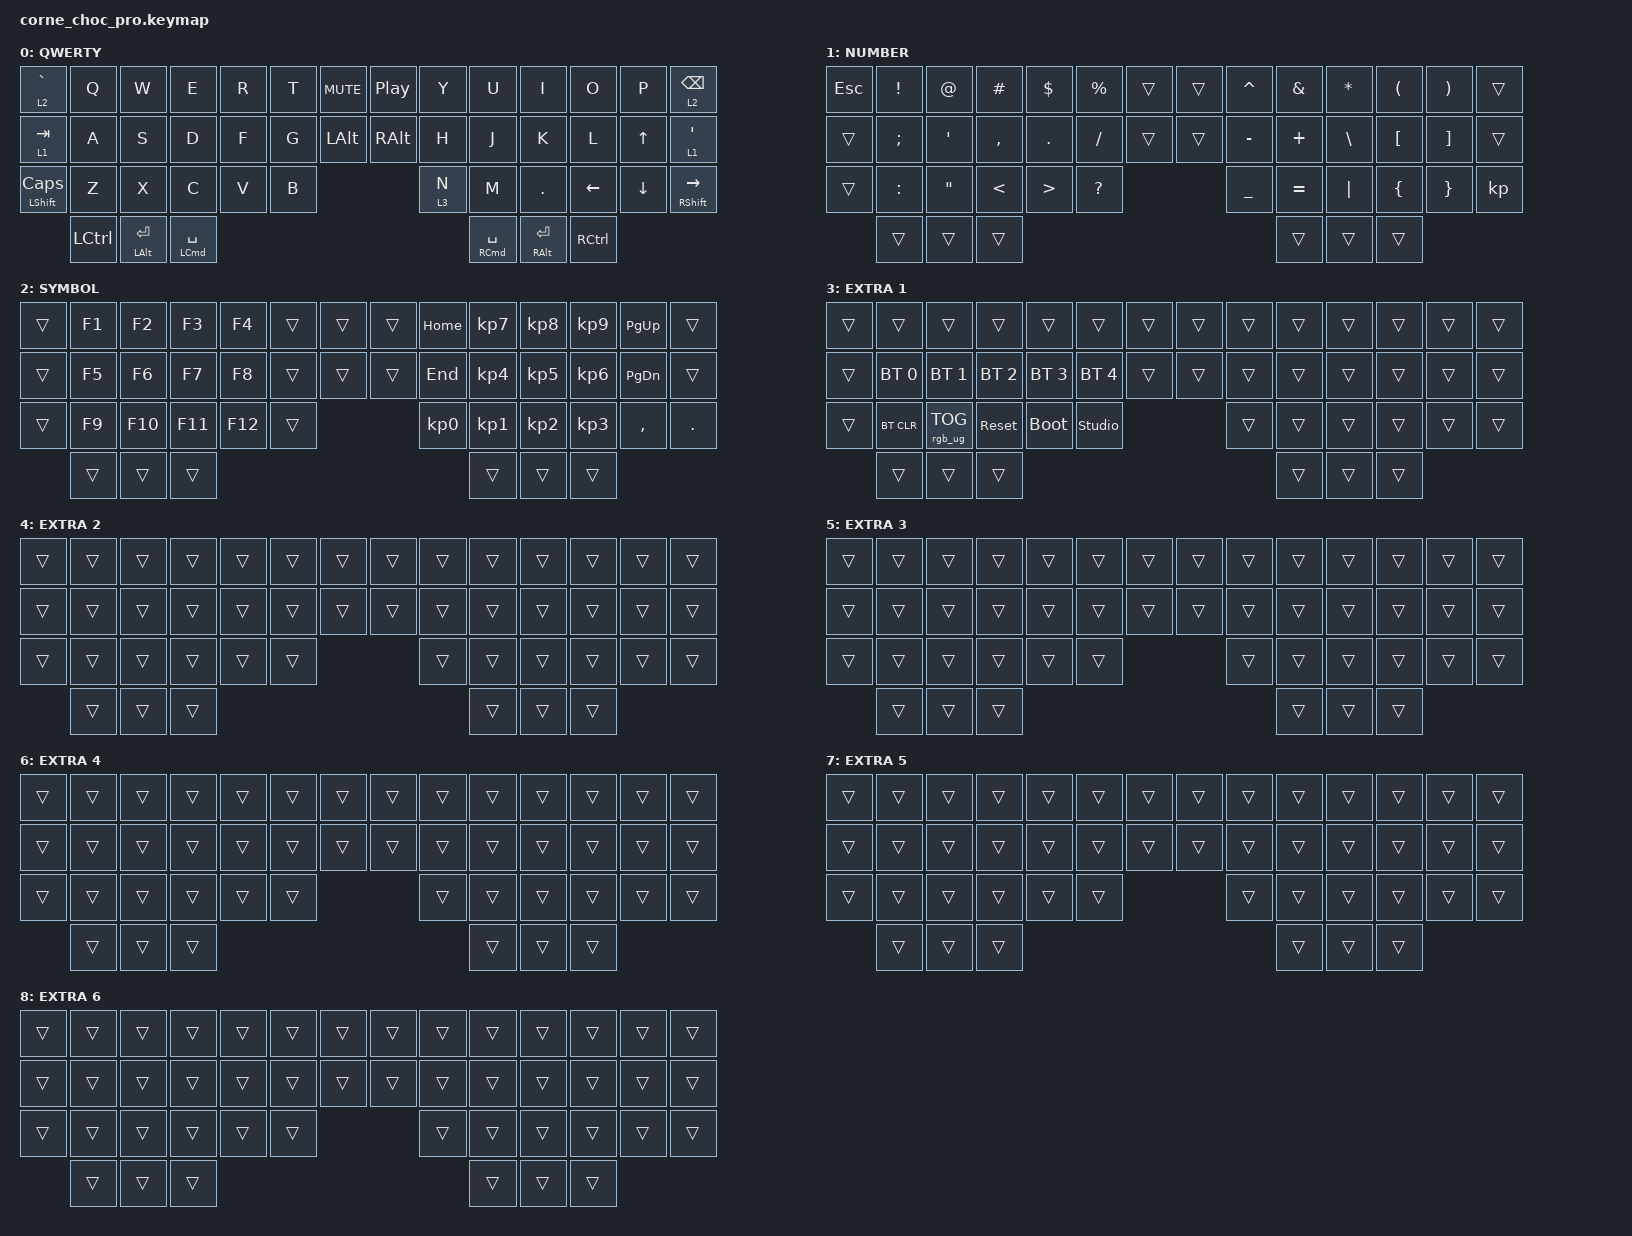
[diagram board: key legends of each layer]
/*
 * Copyright (c) 2020 The ZMK Contributors
 *
 * SPDX-License-Identifier: MIT
 */

#include <behaviors.dtsi>
#include <dt-bindings/zmk/keys.h>
#include <dt-bindings/zmk/bt.h>
#include <dt-bindings/zmk/rgb.h>

/ {
    chosen {
        zmk,physical-layout = &default_layout;
    };
};

/ {
    keymap {
        compatible = "zmk,keymap";

        default_layer {
            display-name = "QWERTY";
            // --------------------------------------------------------------------------------
            // |  `   |  Q  |  W  |  E  |  R  |  T  |  MUTE |  PP   |  Y  |  U  |  I  |  O  |  P  | BSPC |
            // | TAB  |  A  |  S  |  D  |  F  |  G  |  LALT |  RALT |  H  |  J  |  K  |  L  |  ;  |  '   |
            // | SHFT |  Z  |  X  |  C  |  V  |  B  |               |  N  |  M  |  ,  |  .  |  /  | SHFT |
            //                    | CTL | ENT | SPC |               | SPC | RET | CTL |
            bindings = <
                &lt 2 GRAVE     &kp Q &kp W &kp E &kp R &kp T &kp C_MUTE &kp C_PP &kp Y &kp U  &kp I   &kp O    &kp P     &lt 2 BSPC
                &lt 1 TAB       &kp A &kp S &kp D &kp F &kp G &kp LALT   &kp RALT &kp H &kp J  &kp K   &kp L    &kp UP    &lt 1 SQT
                &mt LSHFT CAPS  &kp Z &kp X &kp C &kp V &kp B                   &lt 3 N &kp M  &kp DOT &kp LEFT &kp DOWN  &mt RSHIFT RIGHT
                                &kp LCTRL &mt LALT RET &mt LCMD SPACE      &mt RCMD SPACE &mt RALT RET &kp RCTRL
            >;
            sensor-bindings = <&inc_dec_kp C_VOL_DN C_VOL_UP &inc_dec_kp PG_UP PG_DN &inc_dec_kp C_PREV C_NEXT &inc_dec_kp C_BRI_DN C_BRI_UP>;
        };

        lower_layer {
            display-name = "NUMBER";
            // -----------------------------------------------------------------------------------------
            // |     |  !  |  @  |  #  |  $  |  %  |     |     |  ^  |  &  |  *  |  (  |  )  |     |
            // |     |  ;  |  '  |  ,  |  .  |  /  |     |     |  -  |  +  |  \  |  [  |  ]  |     |
            // |     |  :  |  "  |  <  |  >  |  ?  |           |  _  |  =  | "|" |  {  |  }  |     |
            //                   |     |     |     |           |     |     |     |
            bindings = <
                &kp ESC &kp EXCL   &kp AT   &kp HASH   &kp DLLR   &kp PRCNT &trans &trans &kp CARET &kp AMPS  &kp ASTRK &kp LPAR &kp RPAR &trans
                &trans  &kp SEMI   &kp SQT  &kp COMMA  &kp PERIOD &kp FSLH  &trans &trans &kp MINUS &kp PLUS  &kp BSLH  &kp LBKT &kp RBKT &trans
                &trans  &kp COLON  &kp DQT  &kp LT     &kp GT     &kp QMARK               &kp UNDER &kp EQUAL &kp PIPE  &kp LBRC &kp RBRC &kp
                                            &trans     &trans     &trans                  &trans    &trans    &trans
            >;
        };

        raise_layer {
            display-name = "SYMBOL";
            // -----------------------------------------------------------------------------------------
            // |  TAB |  !  |  @  |  #  |  $  |  %  | LCTRL | RCTRL |  ^  |  &  |  *  |  (  |  )  | BSPC |
            // | CTRL |     |     |     |     |     |  LALT | RALT  |  -  |  =  |  [  |  ]  |  \  |  `   |
            // | SHFT |     |     |     |     |     |               |  _  |  +  |  {  |  }  | "|" |  ~   |
            //                    | GUI |     | SPC |               | ENT |     | ALT |
            // Suggestions
            // &bt BT_SEL 1, 2 and 3: left half, col 6, top, middle, bottom
            // function keys to layer 4, activate with BS hold,
            // key mappings left half only f1 f2 f3 f4 f5 f6
            //                             f7 f8 f9 f10 f12
            //                             &trns &trns &rgb_ug RGB_TOG &sys_reset &bootloader &studio_unlock

            bindings = <
                &trans  &kp F1  &kp F2  &kp F3  &kp F4  &trans  &trans  &trans  &kp HOME  &kp KP_N7 &kp KP_N8 &kp KP_N9 &kp PG_UP &trans
                &trans  &kp F5  &kp F6  &kp F7  &kp F8  &trans  &trans  &trans  &kp END   &kp KP_N4 &kp KP_N5 &kp KP_N6 &kp PG_DN &trans
                &trans  &kp F9  &kp F10 &kp F11 &kp F12 &trans                  &kp KP_N0 &kp KP_N1 &kp KP_N2 &kp KP_N3 &kp COMMA &kp PERIOD
                                        &trans  &trans  &trans                  &trans  &trans  &trans
            >;
        };

        extra_layer_1 {
            display-name = "EXTRA 1";
            // -----------------------------------------------------------------------------------------
            // |  TAB |  1  |  2  |  3  |  4  |  5    |  LCTRL | RCTRL |  6  |  7  |  8  |  9  |  0  | BSPC |
            // | CTRL | BT1 | BT2 | BT3 | BT4 | BT5   |  LALT  | RALT  | LFT | DWN |  UP | RGT |     |      |
            // | SHFT | BTCR| RGB | RST | BOOT| Unlock|        |       |     |     |     |     |     |      |
            //                    | GUI |     | SPC   |        | ENT   |     | ALT |
            bindings = <
                &trans  &trans  &trans  &trans  &trans  &trans  &trans    &trans &trans  &trans  &trans  &trans  &trans  &trans
                &trans &bt BT_SEL 0  &bt BT_SEL 1  &bt BT_SEL 2  &bt BT_SEL 3  &bt BT_SEL 4  &trans    &trans  &trans  &trans  &trans  &trans  &trans  &trans
                &trans &bt BT_CLR  &rgb_ug RGB_TOG &sys_reset   &bootloader  &studio_unlock                    &trans  &trans  &trans  &trans  &trans  &trans
                                                       &trans     &trans       &trans                          &trans  &trans  &trans
            >;
        };

        extra_layer_2 {
            display-name = "EXTRA 2";
            bindings = <
                &trans &trans &trans &trans &trans &trans &trans &trans &trans &trans &trans &trans &trans &trans
                &trans &trans &trans &trans &trans &trans &trans &trans &trans &trans &trans &trans &trans &trans
                &trans &trans &trans &trans &trans &trans               &trans &trans &trans &trans &trans &trans
                                     &trans &trans &trans               &trans &trans &trans
            >;
        };

        extra_layer_3 {
            display-name = "EXTRA 3";
            bindings = <
                &trans &trans &trans &trans &trans &trans &trans &trans &trans &trans &trans &trans &trans &trans
                &trans &trans &trans &trans &trans &trans &trans &trans &trans &trans &trans &trans &trans &trans
                &trans &trans &trans &trans &trans &trans               &trans &trans &trans &trans &trans &trans
                                     &trans &trans &trans               &trans &trans &trans
            >;
        };

        extra_layer_4 {
            display-name = "EXTRA 4";
            bindings = <
                &trans &trans &trans &trans &trans &trans &trans &trans &trans &trans &trans &trans &trans &trans
                &trans &trans &trans &trans &trans &trans &trans &trans &trans &trans &trans &trans &trans &trans
                &trans &trans &trans &trans &trans &trans               &trans &trans &trans &trans &trans &trans
                                     &trans &trans &trans               &trans &trans &trans
            >;
        };

        extra_layer_5 {
            display-name = "EXTRA 5";
            bindings = <
                &trans &trans &trans &trans &trans &trans &trans &trans &trans &trans &trans &trans &trans &trans
                &trans &trans &trans &trans &trans &trans &trans &trans &trans &trans &trans &trans &trans &trans
                &trans &trans &trans &trans &trans &trans               &trans &trans &trans &trans &trans &trans
                                     &trans &trans &trans               &trans &trans &trans
            >;
        };

        extra_layer_6 {
            display-name = "EXTRA 6";
            bindings = <
                &trans &trans &trans &trans &trans &trans &trans &trans &trans &trans &trans &trans &trans &trans
                &trans &trans &trans &trans &trans &trans &trans &trans &trans &trans &trans &trans &trans &trans
                &trans &trans &trans &trans &trans &trans               &trans &trans &trans &trans &trans &trans
                                     &trans &trans &trans               &trans &trans &trans
            >;
        };
    };
};
